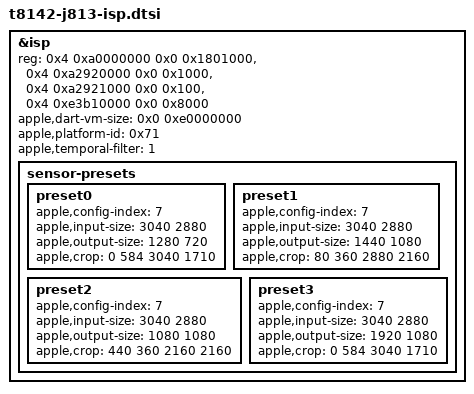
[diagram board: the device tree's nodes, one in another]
// SPDX-License-Identifier: GPL-2.0+ OR MIT
/* J813 ISP watchdog and IMX958 camera configuration. */

/*
 * The J813 IMX958 (sensor version 0x958) as its firmware lists it: 13 configs,
 * among them 3040x2880 (config 7) and a binned 1520x1440 (config 10); half
 * of them report doubled heights and are left out. Its setfile is
 * apple/isp_2224_01XX.dat (from macOS appleh16camerad).
 */
#include "isp-common.dtsi"

&isp {
	reg-names = "coproc", "mbox", "gpio", "wdt";
	reg = <0x4 0xa0000000 0x0 0x1801000>,
	      <0x4 0xa2920000 0x0 0x1000>,
	      <0x4 0xa2921000 0x0 0x100>,
	      <0x4 0xe3b10000 0x0 0x8000>;
	apple,dart-vm-size = <0x0 0xe0000000>;
	apple,platform-id = <0x71>;
	apple,temporal-filter = <1>;

	/*
	 * All presets scale from the full-resolution sensor mode (config 7).
	 * In the binned mode (config 10, 1520x1440) the firmware's AWB keeps
	 * the setfile's default white point and the picture is magenta; in
	 * config 7 it converges.
	 */
	sensor-presets {
		/* 1280x720 */
		preset0 {
			apple,config-index = <7>;
			apple,input-size = <3040 2880>;
			apple,output-size = <1280 720>;
			apple,crop = <0 584 3040 1710>;
		};
		/* 1440x1080 (4:3) */
		preset1 {
			apple,config-index = <7>;
			apple,input-size = <3040 2880>;
			apple,output-size = <1440 1080>;
			apple,crop = <80 360 2880 2160>;
		};
		/* 1080x1080 (1:1) */
		preset2 {
			apple,config-index = <7>;
			apple,input-size = <3040 2880>;
			apple,output-size = <1080 1080>;
			apple,crop = <440 360 2160 2160>;
		};
		/* 1920x1080 */
		preset3 {
			apple,config-index = <7>;
			apple,input-size = <3040 2880>;
			apple,output-size = <1920 1080>;
			apple,crop = <0 584 3040 1710>;
		};
	};
};
